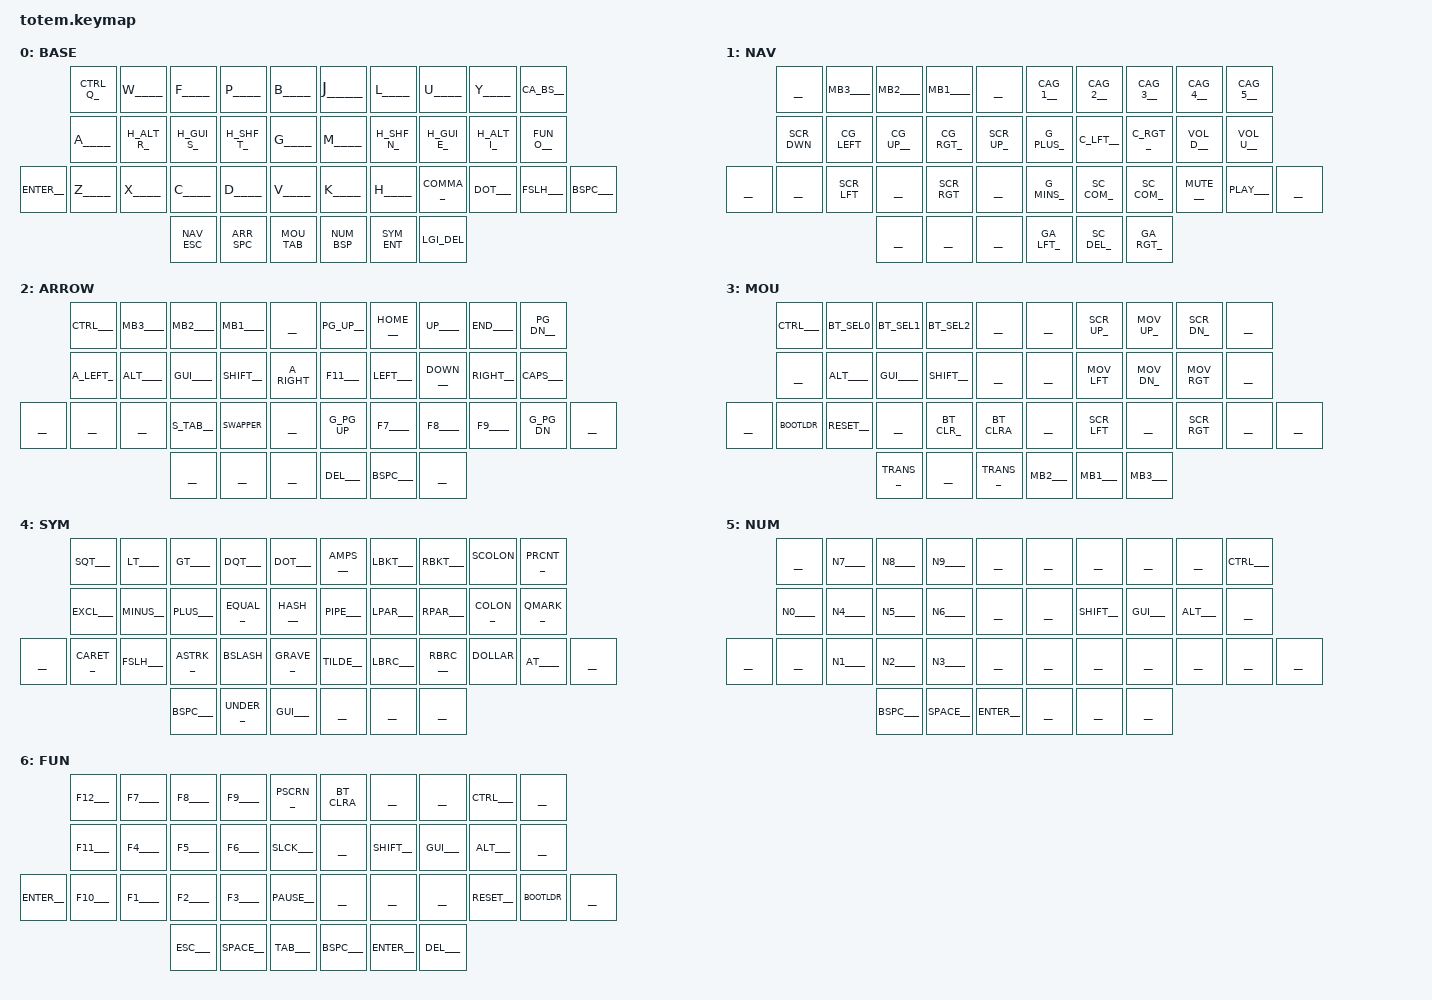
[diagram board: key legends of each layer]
//
//                                                        ▀▀▀▀▀     ▀▀▀▀▀          ▀▀█▀▀
//                                                        ▄▀▀▀▄  ▄  ▄▀▀▀▄  ▄  ▄▀▀▀▄  █  ▄▀▀▀▄
//                                                        █   █  █  █   █  █  █   █  █  █   █
//                                                         ▀▀▀   █   ▀▀▀   █   ▀▀▀   ▀   ▀▀▀
//                                                               █      ▄▄▄█▄▄▄    █   █  
//                                                               ▀      █  █  █     █▄█
//                                                             ▀▀▀▀▀    █  █  █      ▀
//                                                                      ▀  ▀  ▀
//
// ▄▄▄▄▄▄▄▄▄▄▄▄▄▄▄▄▄▄▄▄▄▄▄▄▄▄▄▄▄▄▄▄▄▄▄▄▄▄▄▄▄▄▄▄▄▄▄▄▄▄▄▄▄▄▄▄▄▄▄▄▄▄▄▄▄▄▄▄▄▄▄▄▄▄▄▄▄▄▄▄▄▄▄▄▄▄▄▄▄▄▄▄▄▄▄▄▄▄▄▄▄▄▄▄▄▄▄▄▄▄▄▄▄▄▄▄▄▄▄▄▄▄▄▄▄▄▄▄▄▄▄▄▄▄▄▄▄▄▄▄▄▄▄▄▄▄▄▄▄

#include <behaviors.dtsi>
#include <dt-bindings/zmk/keys.h>
#include <dt-bindings/zmk/bt.h>
#include <dt-bindings/zmk/outputs.h>
#include "includes/mouse.dtsi"
#include "includes/combo.dtsi"
#include "includes/todo.dtsi"

#define BASE    0
#define NAV     1
#define ARROW   2
#define MOU     3
#define SYM     4
#define NUM     5
#define FUN     6

#define AS(keycode) &as LS(keycode) keycode     // Autoshift Macro

// Extra key bindings
#define SWP_POS 23 // for alt tab companion (&kp LS(TAB))

/ {
behaviors {
    as: auto_shift {
    compatible = "zmk,behavior-hold-tap";
    label = "AUTO_SHIFT";
    #binding-cells = <2>;
    tapping-term-ms = <135>;
    quick-tap-ms = <0>;
    flavor = "tap-preferred";
    bindings = <&kp>, <&kp>;
};

hm: homerow_mods {
    compatible = "zmk,behavior-hold-tap";
    label = "HOMEROW_MODS";
    #binding-cells = <2>;
    tapping-term-ms = <175>;
    quick-tap-ms = <0>;
    require-prior-idle-ms = <75>;
    flavor = "tap-preferred";
    bindings = <&kp>, <&kp>;
};

hmp: homerow_mods_pinky {
    compatible = "zmk,behavior-hold-tap";
    label = " ";
    #binding-cells = <2>;
    tapping-term-ms = <200>;
    quick-tap-ms = <0>;
    require-prior-idle-ms = <75>;
    flavor = "tap-preferred";
    bindings = <&kp>, <&kp>;
};
};

// Swapper for smart alt+tab
swapper: swapper {
        compatible = "zmk,behavior-smart-toggle";
        #binding-cells = <0>;
        bindings = <&kp LALT>, <&kp TAB>;
        // things that should not close alt tab ui (shit tab and arrows)
        ignored-key-positions = <SWP_POS 16 17 18 7>;
        // for some reason this format is not working
        // ignored-key-positions = <SWP_POS SW09 SW08 SW07 SW03>; 
};

combos {
        compatible = "zmk,combos";

        COMBO(vol_up,   &kp C_VOL_UP, _F _T)
        COMBO(vol_dn,   &kp C_VOL_DN, _P _S)
        COMBO(med_next, &kp C_NEXT,   _F _P)
        COMBO(med_prev, &kp C_PREV,   _W _F)
        COMBO(med_pp,   &kp C_PP,     _W _B)
        COMBO(med_stop, &kp C_STOP,   _W _P)
        COMBO(med_mute, &kp C_MUTE,   _S _G)
};

#include "includes/defines/base.dtsi"
#include "includes/defines/nav.dtsi"
#include "includes/defines/arrow.dtsi"
#include "includes/defines/mou.dtsi"
#include "includes/defines/sym.dtsi"
#include "includes/defines/num.dtsi"
#include "includes/defines/fun.dtsi"

keymap {
compatible = "zmk,keymap";

BASE {
bindings = <
           __CTRL_Q_  ____W____  ____F____  ____P____  ____B____           ____J____  ____L____  ____U____  ____Y____  __CA_BS__

           ____A____  _H_ALT_R_  _H_GUI_S_  _H_SHF_T_  ____G____           ____M____  _H_SHF_N_  _H_GUI_E_  _H_ALT_I_  __FUN_O__

__ENTER__  ____Z____  ____X____  ____C____  ____D____  ____V____           ____K____  ____H____  __COMMA__  ___DOT___  __FSLH___  __BSPC___

                                 __NAV_ESC  __ARR_SPC  __MOU_TAB           __NUM_BSP  __SYM_ENT  __LGI_DEL
>;
};

NAV {
bindings = <
           _________  __MB3____  __MB2____  __MB1____  _________           __CAG_1__  __CAG_2__  __CAG_3__  __CAG_4__  __CAG_5__

           __SCR_DWN  __CG_LEFT  __CG_UP__  __CG_RGT_  __SCR_UP_           __G_PLUS_  __C_LFT__  __C_RGT__  __VOL_D__  __VOL_U__

_________  _________  __SCR_LFT  _________  __SCR_RGT  _________           __G_MINS_  __SC_COM_  __SC_COM_  __MUTE___  __PLAY___  _________

                                 _________  _________  _________           __GA_LFT_  __SC_DEL_  __GA_RGT_
>;
};

ARROW {
bindings = <
           __CTRL___  __MB3____  __MB2____  __MB1____  _________           __PG_UP__  __HOME___  ___UP____  __END____  __PG_DN__

           __A_LEFT_  __ALT____  __GUI____  __SHIFT__  __A_RIGHT           ___F11___  __LEFT___  __DOWN___  __RIGHT__  __CAPS___

_________  _________  _________  __S_TAB__  __SWAPPER  _________           __G_PG_UP  ___F7____  ___F8____  ___F9____  __G_PG_DN  _________

                                 _________  _________  _________           ___DEL___  __BSPC___  _________
>;
};


MOU {
bindings = <
           __CTRL___  __BT_SEL0  __BT_SEL1  __BT_SEL2  _________           _________  __SCR_UP_  __MOV_UP_  __SCR_DN_  _________

           _________  __ALT____  __GUI____  __SHIFT__  _________           _________  __MOV_LFT  __MOV_DN_  __MOV_RGT  _________

_________  __BOOTLDR  __RESET__  _________  __BT_CLR_  __BT_CLRA           _________  __SCR_LFT  _________  __SCR_RGT  _________  _________

                                 __TRANS__  _________  __TRANS__           ___MB2___  ___MB1___  ___MB3___
>;
};

SYM {
bindings = <
           ___SQT___  ___LT____  ___GT____  ___DQT___  ___DOT___           __AMPS___  __LBKT___  __RBKT___  __SCOLON_  __PRCNT__

           __EXCL___  __MINUS__  __PLUS___  __EQUAL__  __HASH___           __PIPE___  __LPAR___  __RPAR___  __COLON__  __QMARK__

_________  __CARET__  __FSLH___  __ASTRK__  __BSLASH_  __GRAVE__           __TILDE__  __LBRC___  __RBRC___  __DOLLAR_  ___AT____  _________

                                 __BSPC___  __UNDER__  ___GUI___           _________  _________  _________
>;
};

NUM {
bindings = <
           _________  ___N7____  ___N8____  ___N9____  _________           _________  _________  _________  _________  __CTRL___

           ___N0____  ___N4____  ___N5____  ___N6____  _________           _________  __SHIFT__  ___GUI___  ___ALT___  _________

_________  _________  ___N1____  ___N2____  ___N3____  _________           _________  _________  _________  _________  _________  _________

                                 __BSPC___  __SPACE__  __ENTER__           _________  _________  _________
>;
};

FUN {
bindings = <
           ___F12___  ___F7____  ___F8____  ___F9____  __PSCRN__           __BT_CLRA  _________  _________  __CTRL___  _________

           ___F11___  ___F4____  ___F5____  ___F6____  __SLCK___           _________  __SHIFT__  ___GUI___  ___ALT___  _________

__ENTER__  ___F10___  ___F1____  ___F2____  ___F3____  __PAUSE__           _________  _________  _________  __RESET__  __BOOTLDR  _________

                                 ___ESC___  __SPACE__  ___TAB___           __BSPC___  __ENTER__  ___DEL___
>;
};

};
};
